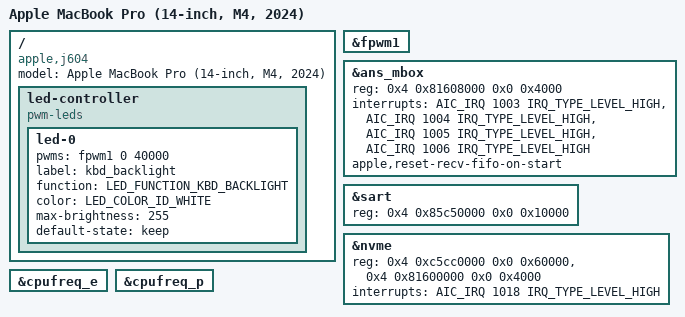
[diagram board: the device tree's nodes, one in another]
// SPDX-License-Identifier: GPL-2.0+ OR MIT
/*
 * Apple MacBook Pro (14-inch, M4, 2024)
 *
 * target-type: J604
 *
 * Copyright The Asahi Linux Contributors
 */

/dts-v1/;

#include "t8132.dtsi"
#include "t8132-jxxx.dtsi"
#include "t8132-j604-input-power.dtsi"
#include "t8132-j604-wireless-performance.dtsi"
#include <dt-bindings/leds/common.h>

/ {
	compatible = "apple,j604", "apple,t8132", "apple,arm-platform";
	model = "Apple MacBook Pro (14-inch, M4, 2024)";

	led-controller {
		compatible = "pwm-leds";
		led-0 {
			pwms = <&fpwm1 0 40000>;
			label = "kbd_backlight";
			function = LED_FUNCTION_KBD_BACKLIGHT;
			color = <LED_COLOR_ID_WHITE>;
			max-brightness = <255>;
			default-state = "keep";
		};
	};
};

&fpwm1 {
	status = "okay";
};

/*
 * ANS storage resources from the local Mac16,1 ADT capture. NVMe uses
 * /arm-io/ans reg[9], widened to cover the linear queue doorbells and
 * NVMMU registers, as in GravityLinux/linux 4fc326f6c25c t8132.dtsi.
 * ASC is reg[0], with its mailbox at +0x8000.
 */
&ans_mbox {
	reg = <0x4 0x81608000 0x0 0x4000>;
	interrupts = <AIC_IRQ 1003 IRQ_TYPE_LEVEL_HIGH>,
		<AIC_IRQ 1004 IRQ_TYPE_LEVEL_HIGH>,
		<AIC_IRQ 1005 IRQ_TYPE_LEVEL_HIGH>,
		<AIC_IRQ 1006 IRQ_TYPE_LEVEL_HIGH>;
	/*
	 * U-Boot sleeps and resets ANS at handoff; a stale crash message left
	 * in the I2A FIFO makes Linux latch RTKit as crashed before it can
	 * reset ANS. Drop it at channel start (spec 02 §2.2).
	 */
	apple,reset-recv-fifo-on-start;
	status = "okay";
};

&sart {
	reg = <0x4 0x85c50000 0x0 0x10000>;
	status = "okay";
};

&nvme {
	reg = <0x4 0xc5cc0000 0x0 0x60000>,
	      <0x4 0x81600000 0x0 0x4000>;
	reg-names = "nvme", "ans";
	interrupts = <AIC_IRQ 1018 IRQ_TYPE_LEVEL_HIGH>;
	status = "okay";
};

/* Spec 01 §1.6: J604 CPU performance controllers. */
&cpufreq_e {
	status = "okay";
};

&cpufreq_p {
	status = "okay";
};
